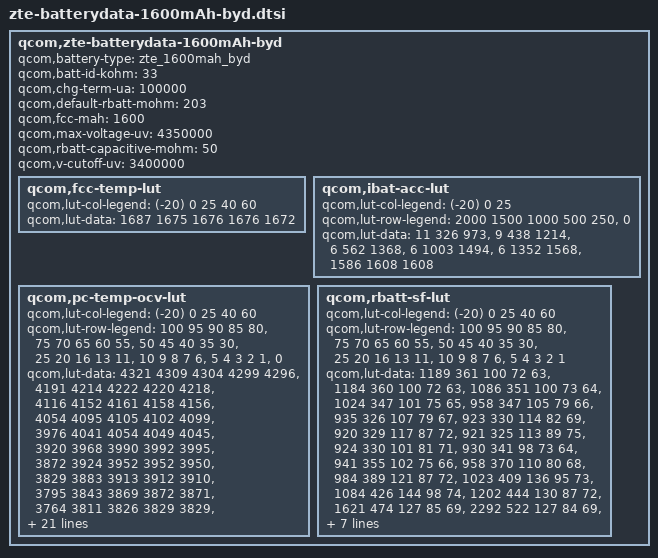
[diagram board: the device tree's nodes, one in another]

qcom,zte-batterydata-1600mAh-byd {
	qcom,battery-type = "zte_1600mah_byd";
	qcom,batt-id-kohm = <33>;
	qcom,chg-term-ua = <100000>;
	qcom,default-rbatt-mohm = <203>;
	qcom,fcc-mah = <1600>;
	qcom,max-voltage-uv = <4350000>;
	qcom,rbatt-capacitive-mohm = <50>;
	qcom,v-cutoff-uv = <3400000>;

	qcom,fcc-temp-lut {
		qcom,lut-col-legend = <(-20) 0 25 40 60>;
		qcom,lut-data = <1687 1675 1676 1676 1672>;
	};

	qcom,ibat-acc-lut {
		qcom,lut-col-legend = <(-20) 0 25>;
		qcom,lut-row-legend = <2000 1500 1000 500 250>,
					<0>;
		qcom,lut-data = <11 326 973>,
				<9 438 1214>,
				<6 562 1368>,
				<6 1003 1494>,
				<6 1352 1568>,
				<1586 1608 1608>;
	};

	qcom,pc-temp-ocv-lut {
		qcom,lut-col-legend = <(-20) 0 25 40 60>;
		qcom,lut-row-legend = <100 95 90 85 80>,
					<75 70 65 60 55>,
					<50 45 40 35 30>,
					<25 20 16 13 11>,
					<10 9 8 7 6>,
					<5 4 3 2 1>,
					<0>;
		qcom,lut-data = <4321 4309 4304 4299 4296>,
				<4191 4214 4222 4220 4218>,
				<4116 4152 4161 4158 4156>,
				<4054 4095 4105 4102 4099>,
				<3976 4041 4054 4049 4045>,
				<3920 3968 3990 3992 3995>,
				<3872 3924 3952 3952 3950>,
				<3829 3883 3913 3912 3910>,
				<3795 3843 3869 3872 3871>,
				<3764 3811 3826 3829 3829>,
				<3736 3788 3796 3796 3794>,
				<3710 3770 3780 3780 3776>,
				<3688 3757 3774 3772 3767>,
				<3668 3742 3770 3770 3763>,
				<3649 3722 3762 3762 3752>,
				<3628 3686 3732 3730 3722>,
				<3600 3634 3660 3658 3654>,
				<3570 3580 3596 3597 3594>,
				<3538 3545 3555 3556 3553>,
				<3508 3524 3530 3532 3530>,
				<3492 3514 3520 3524 3522>,
				<3472 3504 3512 3516 3516>,
				<3452 3494 3504 3508 3508>,
				<3430 3483 3496 3500 3498>,
				<3404 3470 3486 3488 3484>,
				<3374 3451 3464 3466 3455>,
				<3334 3414 3422 3420 3408>,
				<3282 3360 3364 3362 3349>,
				<3208 3285 3290 3290 3275>,
				<3113 3182 3191 3193 3176>,
				<3006 3018 3000 3000 3012>;
	};

	qcom,rbatt-sf-lut {
		qcom,lut-col-legend = <(-20) 0 25 40 60>;
		qcom,lut-row-legend = <100 95 90 85 80>,
					<75 70 65 60 55>,
					<50 45 40 35 30>,
					<25 20 16 13 11>,
					<10 9 8 7 6>,
					<5 4 3 2 1>;
		qcom,lut-data = <1189 361 100 72 63>,
				<1184 360 100 72 63>,
				<1086 351 100 73 64>,
				<1024 347 101 75 65>,
				<958 347 105 79 66>,
				<935 326 107 79 67>,
				<923 330 114 82 69>,
				<920 329 117 87 72>,
				<921 325 113 89 75>,
				<924 330 101 81 71>,
				<930 341 98 73 64>,
				<941 355 102 75 66>,
				<958 370 110 80 68>,
				<984 389 121 87 72>,
				<1023 409 136 95 73>,
				<1084 426 144 98 74>,
				<1202 444 130 87 72>,
				<1621 474 127 85 69>,
				<2292 522 127 84 69>,
				<3376 590 131 84 68>,
				<4243 642 136 85 69>,
				<5462 710 141 88 71>,
				<7216 809 150 91 72>,
				<9712 950 162 96 74>,
				<13331 1219 176 100 74>,
				<18669 1651 194 102 73>,
				<26583 2342 214 104 74>,
				<38398 3408 254 113 78>,
				<56568 5302 323 129 85>,
				<81513 8504 447 158 97>;
	};
};
/* TEST_DB_ID=TEST_ID_NOT_SET */

